# MKV10Z1287 register map
Vendor: Freescale Semiconductor, Inc.; Series: Kinetis_V; File version: 1.6
CPU: CM0PLUS r0p0, little endian, no MPU, no FPU, VTOR, 2 interrupt priority bits
Registers are 32-bit, read-write, reset 0x0 unless marked. A register's access mark holds for its fields unless they carry their own. Offsets are from the block's base; [hi:lo] are bit positions; {n}, {i} and the like mark numbered series; 'fields as' and 'values as' point back to an identical list.

## FTFA_FlashConfig — Flash configuration field
Base 0x00000400; register names take the prefix NV_
0x00 BACKKEY3 8-bit ro reset 0xFF — Backdoor Comparison Key 3.
  [7:0] KEY — Backdoor Comparison Key.
0x01 BACKKEY2 8-bit ro reset 0xFF — Backdoor Comparison Key 2.
  [7:0] KEY — Backdoor Comparison Key.
0x02 BACKKEY1 8-bit ro reset 0xFF — Backdoor Comparison Key 1.
  [7:0] KEY — Backdoor Comparison Key.
0x03 BACKKEY0 8-bit ro reset 0xFF — Backdoor Comparison Key 0.
  [7:0] KEY — Backdoor Comparison Key.
0x04 BACKKEY7 8-bit ro reset 0xFF — Backdoor Comparison Key 7.
  [7:0] KEY — Backdoor Comparison Key.
0x05 BACKKEY6 8-bit ro reset 0xFF — Backdoor Comparison Key 6.
  [7:0] KEY — Backdoor Comparison Key.
0x06 BACKKEY5 8-bit ro reset 0xFF — Backdoor Comparison Key 5.
  [7:0] KEY — Backdoor Comparison Key.
0x07 BACKKEY4 8-bit ro reset 0xFF — Backdoor Comparison Key 4.
  [7:0] KEY — Backdoor Comparison Key.
0x08 FPROT3 8-bit ro reset 0xFF — Non-volatile P-Flash Protection 1 - Low Register
  [7:0] PROT — P-Flash Region Protect
0x09 FPROT2 8-bit ro reset 0xFF — Non-volatile P-Flash Protection 1 - High Register
  [7:0] PROT — P-Flash Region Protect
0x0A FPROT1 8-bit ro reset 0xFF — Non-volatile P-Flash Protection 0 - Low Register
  [7:0] PROT — P-Flash Region Protect
0x0B FPROT0 8-bit ro reset 0xFF — Non-volatile P-Flash Protection 0 - High Register
  [7:0] PROT — P-Flash Region Protect
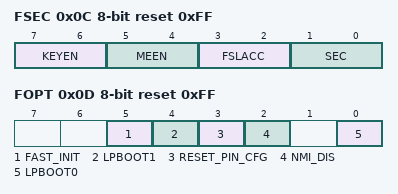
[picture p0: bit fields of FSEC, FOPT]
0x0C FSEC 8-bit ro reset 0xFF — Non-volatile Flash Security Register
  [7:6] KEYEN — Backdoor Key Security Enable
    2=Backdoor key access enabled; 3=Backdoor key access disabled
  [5:4] MEEN
    2=Mass erase is disabled; 3=Mass erase is enabled
  [3:2] FSLACC — Freescale Failure Analysis Access Code
    2=Freescale factory access denied; 3=Freescale factory access granted
  [1:0] SEC — Flash Security
    2=MCU security status is unsecure; 3=MCU security status is secure
0x0D FOPT 8-bit ro reset 0xFF — Non-volatile Flash Option Register
  [5] FAST_INIT
    0=Slower initialization; 1=Fast Initialization
  [4] LPBOOT1
    0=Core and system clock divider (OUTDIV1) is 0x7 (divide by 8) when LPBOOT0=0 or 0x3 (divide by 4) when LPBOOT0=1; 1=Core and system clock divider (OUTDIV1) is 0x1 (divide by 2) when LPBOOT0=0 or 0x0 (divide by 1) when LPBOOT0=1
  [3] RESET_PIN_CFG
    0=RESET pin is disabled following a POR and cannot be enabled as reset function; 1=RESET_b pin is dedicated
  [2] NMI_DIS
    0=NMI interrupts are always blocked; 1=NMI_b pin/interrupts reset default to enabled
  [0] LPBOOT0
    0=Core and system clock divider (OUTDIV1) is 0x7 (divide by 8) when LPBOOT1=0 or 0x1 (divide by 2) when LPBOOT1=1; 1=Core and system clock divider (OUTDIV1) is 0x3 (divide by 4) when LPBOOT1=0 or 0x0 (divide by 1) when LPBOOT1=1

## DMAMUX — DMA channel multiplexor
Base 0x40021000; register names take the prefix DMAMUX_
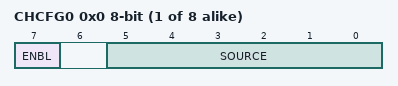
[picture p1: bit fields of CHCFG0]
{0x0+i} CHCFG{i} (i=0..7) 8-bit — Channel Configuration register
  [7] ENBL — DMA Channel Enable
    0=DMA channel is disabled. This mode is primarily used during configuration of the DMAMux. The DMA has separate channel enables/disables, which should be used to disable or reconfigure a DMA channel.; 1=DMA channel is enabled
  [5:0] SOURCE — DMA Channel Source (Slot)

## CRC — Cyclic Redundancy Check
Base 0x40032000; register names take the prefix CRC_
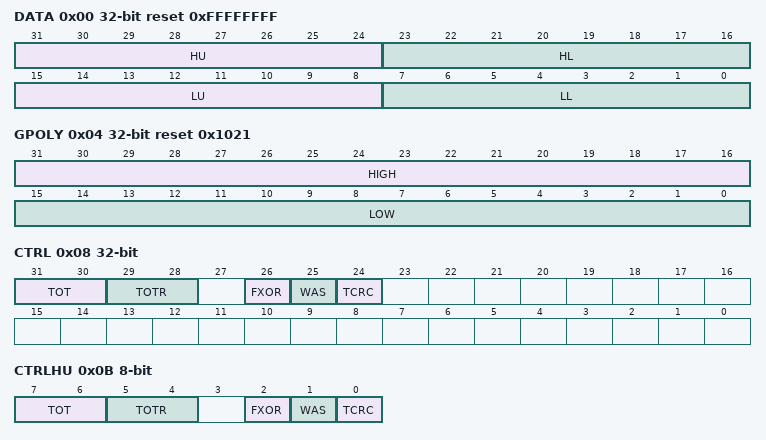
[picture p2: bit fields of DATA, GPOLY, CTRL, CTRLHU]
0x00 DATA reset 0xFFFFFFFF (CRC view) — CRC Data register
  [31:24] HU — CRC High Upper Byte
  [23:16] HL — CRC High Lower Byte
  [15:8] LU — CRC Low Upper Byte
  [7:0] LL — CRC Low Lower Byte
0x00 DATAL 16-bit reset 0xFFFF (CRC view) — CRC_DATAL register.
  [15:0] DATAL — DATAL stores the lower 16 bits of the 16/32 bit CRC
0x00 DATALL 8-bit reset 0xFF (CRC view) — CRC_DATALL register.
  [7:0] DATALL — CRCLL stores the first 8 bits of the 32 bit DATA
0x01 DATALU 8-bit reset 0xFF — CRC_DATALU register.
  [7:0] DATALU — DATALL stores the second 8 bits of the 32 bit CRC
0x02 DATAH 16-bit reset 0xFFFF (CRC view) — CRC_DATAH register.
  [15:0] DATAH — DATAH stores the high 16 bits of the 16/32 bit CRC
0x02 DATAHL 8-bit reset 0xFF (CRC view) — CRC_DATAHL register.
  [7:0] DATAHL — DATAHL stores the third 8 bits of the 32 bit CRC
0x03 DATAHU 8-bit reset 0xFF — CRC_DATAHU register.
  [7:0] DATAHU — DATAHU stores the fourth 8 bits of the 32 bit CRC
0x04 GPOLY reset 0x1021 (CRC view) — CRC Polynomial register
  [31:16] HIGH — High Polynominal Half-word
  [15:0] LOW — Low Polynominal Half-word
0x04 GPOLYL 16-bit reset 0xFFFF (CRC view) — CRC_GPOLYL register.
  [15:0] GPOLYL — POLYL stores the lower 16 bits of the 16/32 bit CRC polynomial value
0x04 GPOLYLL 8-bit reset 0xFF (CRC view) — CRC_GPOLYLL register.
  [7:0] GPOLYLL — POLYLL stores the first 8 bits of the 32 bit CRC
0x05 GPOLYLU 8-bit reset 0xFF — CRC_GPOLYLU register.
  [7:0] GPOLYLU — POLYLL stores the second 8 bits of the 32 bit CRC
0x06 GPOLYH 16-bit reset 0xFFFF (CRC view) — CRC_GPOLYH register.
  [15:0] GPOLYH — POLYH stores the high 16 bits of the 16/32 bit CRC polynomial value
0x06 GPOLYHL 8-bit reset 0xFF (CRC view) — CRC_GPOLYHL register.
  [7:0] GPOLYHL — POLYHL stores the third 8 bits of the 32 bit CRC
0x07 GPOLYHU 8-bit reset 0xFF — CRC_GPOLYHU register.
  [7:0] GPOLYHU — POLYHU stores the fourth 8 bits of the 32 bit CRC
0x08 CTRL — CRC Control register
  [31:30] TOT — Type Of Transpose For Writes
    0=No transposition; 1=Bits in bytes are transposed; bytes are not transposed; 2=Both bits in bytes and bytes are transposed; 3=Only bytes are transposed; no bits in a byte are transposed
  [29:28] TOTR — Type Of Transpose For Read
    values as TOT
  [26] FXOR — Complement Read Of CRC Data Register
    0=No XOR on reading; 1=Invert or complement the read value of the CRC Data register
  [25] WAS — Write CRC Data Register As Seed
    0=Writes to the CRC data register are data values; 1=Writes to the CRC data register are seed values
  [24] TCRC — Width of CRC protocol.
    0=16-bit CRC protocol; 1=32-bit CRC protocol
0x0B CTRLHU 8-bit — CRC_CTRLHU register.
  [7:6] TOT
    0=No Transposition; 1=Bits in bytes are transposed, bytes are not transposed; 2=Both bits in bytes and bytes are transposed; 3=Only bytes are transposed; no bits in a byte are transposed
  [5:4] TOTR
    values as TOT
  [2] FXOR
    0=No XOR on reading; 1=Invert or complement the read value of CRC data register
  [1] WAS
    0=Writes to CRC data register are data values; 1=Writes to CRC data reguster are seed values
  [0] TCRC
    0=16-bit CRC protocol; 1=32-bit CRC protocol
